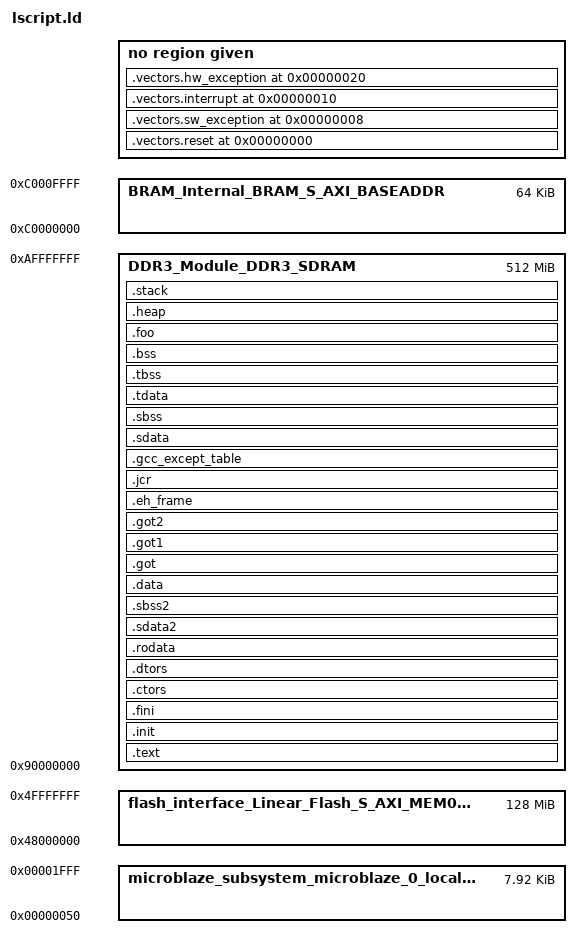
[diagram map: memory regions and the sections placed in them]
/*******************************************************************/
/*                                                                 */
/* This file is automatically generated by linker script generator.*/
/*                                                                 */
/* Version: Xilinx EDK 14.6 EDK_P.68d                                */
/*                                                                 */
/* Copyright (c) 2010 Xilinx, Inc.  All rights reserved.           */
/*                                                                 */
/* Description : MicroBlaze Linker Script                          */
/*                                                                 */
/*******************************************************************/

_STACK_SIZE = DEFINED(_STACK_SIZE) ? _STACK_SIZE : 0x1E000;
_HEAP_SIZE = DEFINED(_HEAP_SIZE) ? _HEAP_SIZE : 0x40000;

/* Define Memories in the system */

MEMORY
{
   BRAM_Internal_BRAM_S_AXI_BASEADDR : ORIGIN = 0xC0000000, LENGTH = 0x00010000
   microblaze_subsystem_microblaze_0_local_memory_LocalMemory_Cntlr_I_microblaze_subsystem_microblaze_0_local_memory_LocalMemory_Cntlr_D : ORIGIN = 0x00000050, LENGTH = 0x00001FB0
   DDR3_Module_DDR3_SDRAM : ORIGIN = 0x90000000, LENGTH = 0x20000000
   flash_interface_Linear_Flash_S_AXI_MEM0_BASEADDR : ORIGIN = 0x48000000, LENGTH = 0x08000000
}

/* Specify the default entry point to the program */

ENTRY(_start)

/* Define the sections, and where they are mapped in memory */

SECTIONS
{
.vectors.reset 0x00000000 : {
   KEEP (*(.vectors.reset))
} 

.vectors.sw_exception 0x00000008 : {
   KEEP (*(.vectors.sw_exception))
} 

.vectors.interrupt 0x00000010 : {
   KEEP (*(.vectors.interrupt))
} 

.vectors.hw_exception 0x00000020 : {
   KEEP (*(.vectors.hw_exception))
} 

.text : {
   *(.text)
   *(.text.*)
   *(.gnu.linkonce.t.*)
} > DDR3_Module_DDR3_SDRAM

.init : {
   KEEP (*(.init))
} > DDR3_Module_DDR3_SDRAM

.fini : {
   KEEP (*(.fini))
} > DDR3_Module_DDR3_SDRAM

.ctors : {
   __CTOR_LIST__ = .;
   ___CTORS_LIST___ = .;
   KEEP (*crtbegin.o(.ctors))
   KEEP (*(EXCLUDE_FILE(*crtend.o) .ctors))
   KEEP (*(SORT(.ctors.*)))
   KEEP (*(.ctors))
   __CTOR_END__ = .;
   ___CTORS_END___ = .;
} > DDR3_Module_DDR3_SDRAM

.dtors : {
   __DTOR_LIST__ = .;
   ___DTORS_LIST___ = .;
   KEEP (*crtbegin.o(.dtors))
   KEEP (*(EXCLUDE_FILE(*crtend.o) .dtors))
   KEEP (*(SORT(.dtors.*)))
   KEEP (*(.dtors))
   PROVIDE(__DTOR_END__ = .);
   PROVIDE(___DTORS_END___ = .);
} > DDR3_Module_DDR3_SDRAM

.rodata : {
   __rodata_start = .;
   *(.rodata)
   *(.rodata.*)
   *(.gnu.linkonce.r.*)
   __rodata_end = .;
} > DDR3_Module_DDR3_SDRAM

.sdata2 : {
   . = ALIGN(8);
   __sdata2_start = .;
   *(.sdata2)
   *(.sdata2.*)
   *(.gnu.linkonce.s2.*)
   . = ALIGN(8);
   __sdata2_end = .;
} > DDR3_Module_DDR3_SDRAM

.sbss2 : {
   __sbss2_start = .;
   *(.sbss2)
   *(.sbss2.*)
   *(.gnu.linkonce.sb2.*)
   __sbss2_end = .;
} > DDR3_Module_DDR3_SDRAM

.data : {
   . = ALIGN(4);
   __data_start = .;
   *(.data)
   *(.data.*)
   *(.gnu.linkonce.d.*)
   __data_end = .;
} > DDR3_Module_DDR3_SDRAM

.got : {
   *(.got)
} > DDR3_Module_DDR3_SDRAM

.got1 : {
   *(.got1)
} > DDR3_Module_DDR3_SDRAM

.got2 : {
   *(.got2)
} > DDR3_Module_DDR3_SDRAM

.eh_frame : {
   *(.eh_frame)
} > DDR3_Module_DDR3_SDRAM

.jcr : {
   *(.jcr)
} > DDR3_Module_DDR3_SDRAM

.gcc_except_table : {
   *(.gcc_except_table)
} > DDR3_Module_DDR3_SDRAM

.sdata : {
   . = ALIGN(8);
   __sdata_start = .;
   *(.sdata)
   *(.sdata.*)
   *(.gnu.linkonce.s.*)
   __sdata_end = .;
} > DDR3_Module_DDR3_SDRAM

.sbss (NOLOAD) : {
   . = ALIGN(4);
   __sbss_start = .;
   *(.sbss)
   *(.sbss.*)
   *(.gnu.linkonce.sb.*)
   . = ALIGN(8);
   __sbss_end = .;
} > DDR3_Module_DDR3_SDRAM

.tdata : {
   __tdata_start = .;
   *(.tdata)
   *(.tdata.*)
   *(.gnu.linkonce.td.*)
   __tdata_end = .;
} > DDR3_Module_DDR3_SDRAM

.tbss : {
   __tbss_start = .;
   *(.tbss)
   *(.tbss.*)
   *(.gnu.linkonce.tb.*)
   __tbss_end = .;
} > DDR3_Module_DDR3_SDRAM

.bss (NOLOAD) : {
   . = ALIGN(4);
   __bss_start = .;
   *(.bss)
   *(.bss.*)
   *(.gnu.linkonce.b.*)
   *(COMMON)
   . = ALIGN(4);
   __bss_end = .;
} > DDR3_Module_DDR3_SDRAM

.foo : {
   __foo_start = .;
   *(.foo)
   __foo_end = .;
} > DDR3_Module_DDR3_SDRAM

_SDA_BASE_ = __sdata_start + ((__sbss_end - __sdata_start) / 2 );

_SDA2_BASE_ = __sdata2_start + ((__sbss2_end - __sdata2_start) / 2 );

/* Generate Stack and Heap definitions */

.heap (NOLOAD) : {
   . = ALIGN(8);
   _heap = .;
   _heap_start = .;
   . += _HEAP_SIZE;
   _heap_end = .;
} > DDR3_Module_DDR3_SDRAM

.stack (NOLOAD) : {
   _stack_end = .;
   . += _STACK_SIZE;
   . = ALIGN(8);
   _stack = .;
   __stack = _stack;
} > DDR3_Module_DDR3_SDRAM

_end = .;
}

